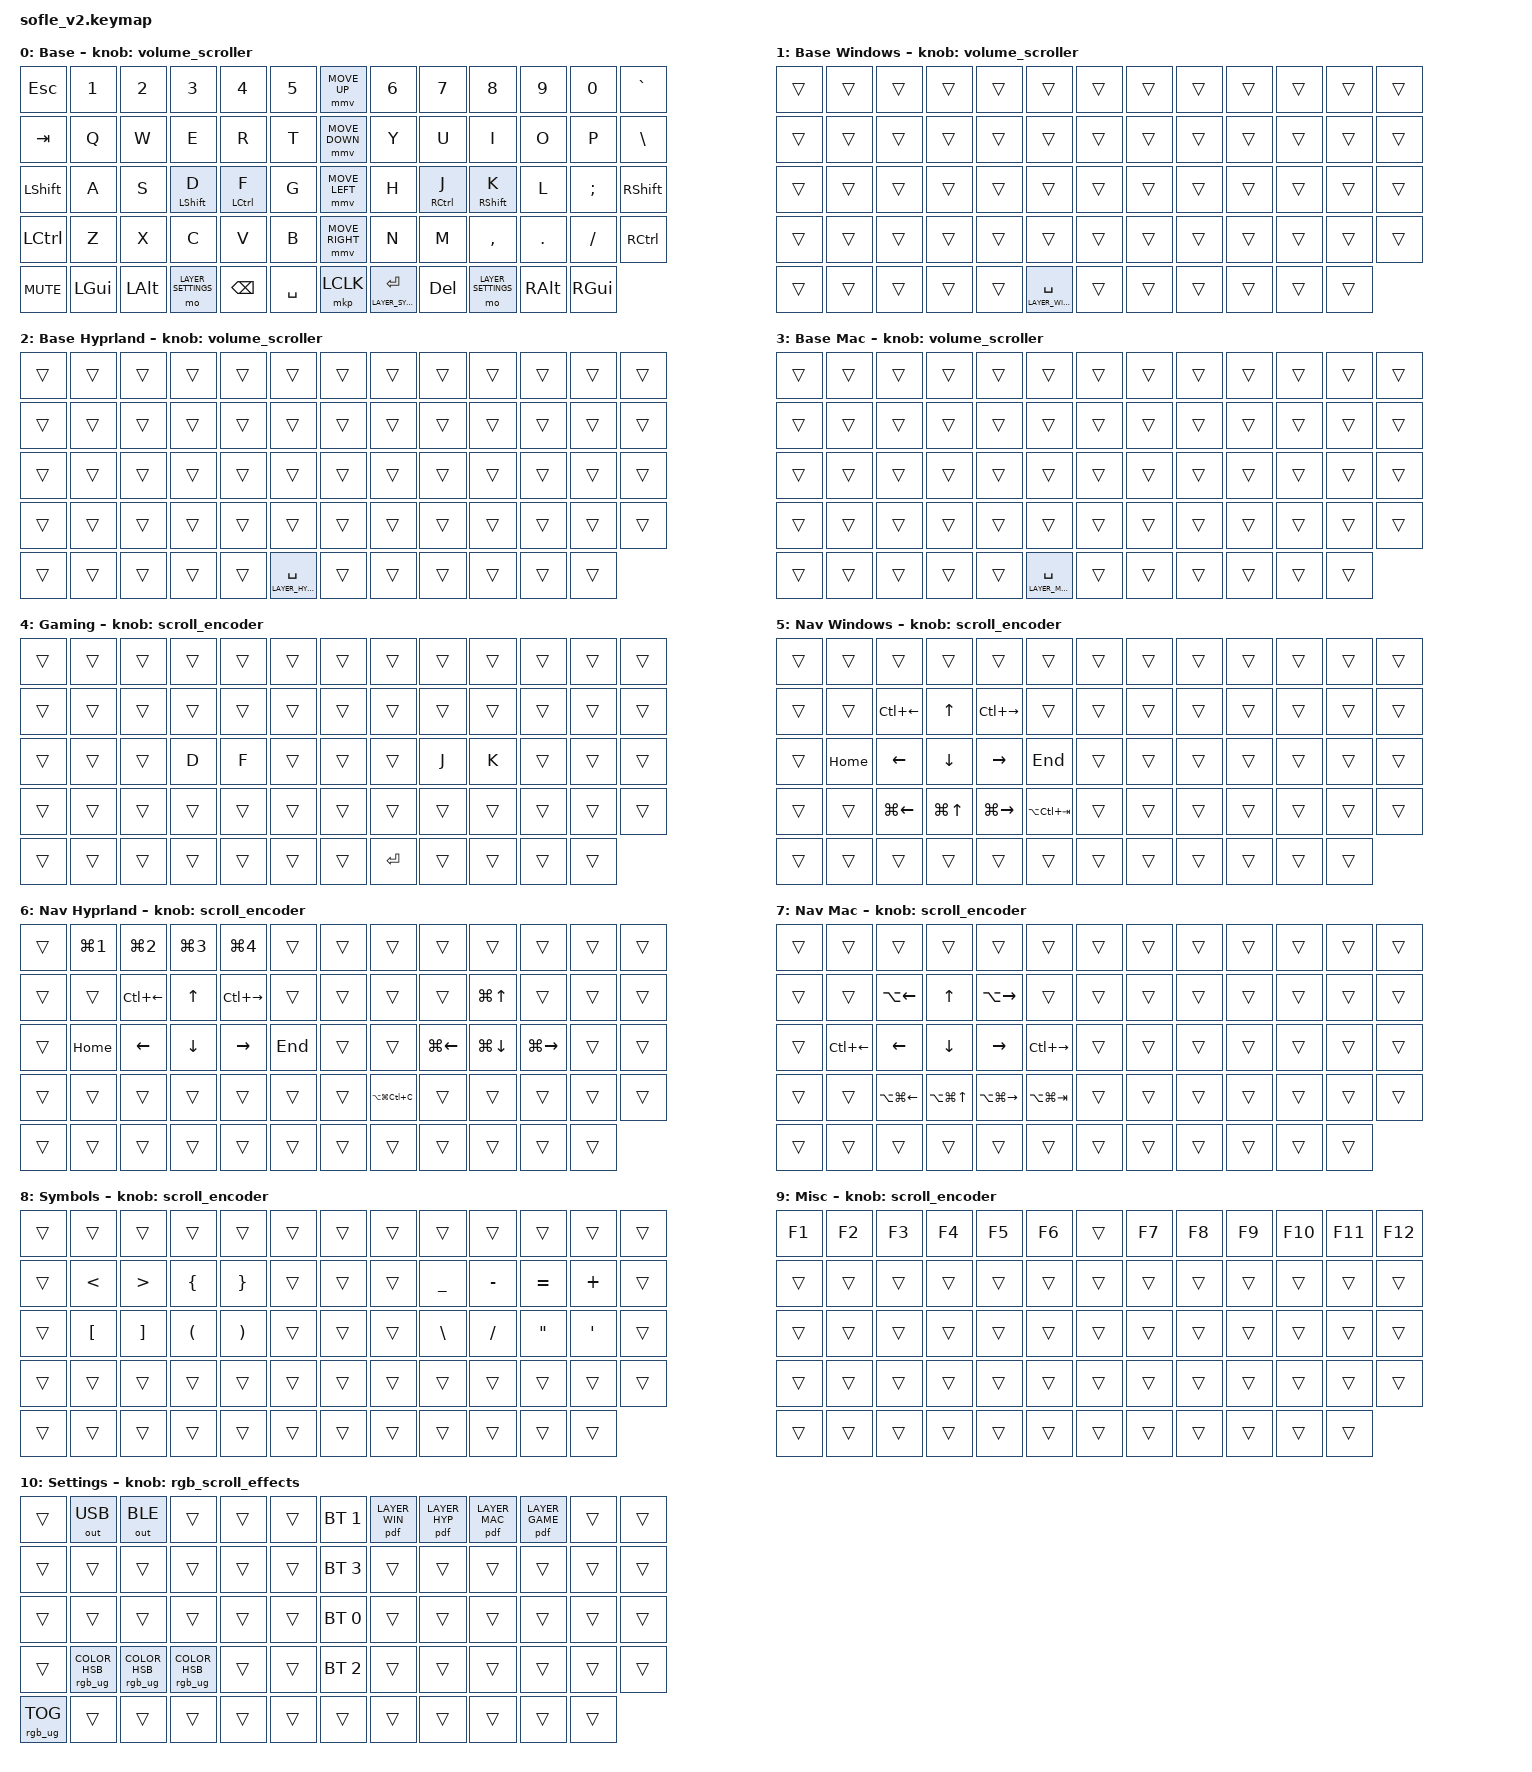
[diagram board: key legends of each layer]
#define ZMK_POINTING_DEFAULT_MOVE_VAL 1200  // 600
#define ZMK_POINTING_DEFAULT_SCRL_VAL 25   // 10

#include <input/processors.dtsi>
#include <zephyr/dt-bindings/input/input-event-codes.h>
#include <behaviors.dtsi>
#include <dt-bindings/zmk/bt.h>
#include <dt-bindings/zmk/keys.h>
#include <dt-bindings/zmk/outputs.h>
#include <dt-bindings/zmk/pointing.h>
#include <dt-bindings/zmk/rgb.h>

#define LAYER_WIN 1
#define LAYER_HYP 2
#define LAYER_MAC 3
#define LAYER_GAME 4
#define LAYER_WIN_NAV 5
#define LAYER_HYP_NAV 6
#define LAYER_MAC_NAV 7
#define LAYER_SYMBOLS 8
#define LAYER_MISC 9
#define LAYER_SETTINGS 10

&mmv_input_listener { input-processors = <&zip_xy_scaler 2 1>; };

&msc_input_listener { input-processors = <&zip_scroll_scaler 2 1>; };

&msc {
    acceleration-exponent = <1>;      // 0
    time-to-max-speed-ms = <100>;       // 300
    delay-ms = <0>;                   // 0
};

&mmv {
    time-to-max-speed-ms = <500>;
    acceleration-exponent = <1>;
    trigger-period-ms = <16>;
};

&soft_off { hold-time-ms = <2000>; };

&lt {
    flavor = "hold-preferred";
    require-prior-idle-ms = <75>;
    quick-tap-ms = <100>;
    tapping-term-ms = <220>;
};

/ {
    scroll_encoder: scroll_encoder {
        compatible = "zmk,behavior-sensor-rotate";
        #sensor-binding-cells = <0>;
        bindings = <&msc SCRL_DOWN>, <&msc SCRL_UP>;

        tap-ms = <100>;
    };

    behaviors {
        pdf: pdf {
            compatible = "zmk,behaviour-persistent-default-layer";
            #binding-cells = <1>;
        };

        hml: home_row_mod_left {
            compatible = "zmk,behavior-hold-tap";
            #binding-cells = <2>;
            flavor = "balanced";
            require-prior-idle-ms = <75>;
            tapping-term-ms = <175>;
            quick-tap-ms = <100>;
            bindings = <&kp>, <&kp>;

            //  hold-trigger-key-positions = <6 7 8 9 10 11 18 19 20 21 22 23 30 31 32 33 34 35 42 43 44 45 46 47 53 54 55 56 57>;
            //  hold-trigger-on-release;

            hold-trigger-key-positions = <7 20 33 46 47 34 21 8 9 22 35 48 49 36 23 10 11 24 37 50 51 38 25 12>;
            hold-trigger-on-release;
            label = "Home Row Mod Left";
        };

        hmr: home_row_mod_right {
            compatible = "zmk,behavior-hold-tap";
            #binding-cells = <2>;
            flavor = "balanced";
            require-prior-idle-ms = <75>;
            tapping-term-ms = <175>;
            quick-tap-ms = <100>;
            bindings = <&kp>, <&kp>;

            // hold-trigger-key-positions = < 0 1 2 3 4 5 12 13 14 15 16 17 24 25 26 27 28 29 36 37 38 39 40 41 48 49 50 51 52>; // List of keys on the left side of the keyboard
            // hold-trigger-on-release;

            hold-trigger-key-positions = <5 18 31 44 43 42 41 40 39 26 27 28 29 30 17 16 15 14 13 0 1 2 3 4 0 1 2 3 4 5 13 14 15 16 17 18 26 27 28 29 30 31 39 40 41 42 43 44>;
            hold-trigger-on-release;
            label = "Home Row Mod Right";
        };

        rgb_brightness: rgb_brightness {
            compatible = "zmk,behavior-sensor-rotate";
            label = "RGB_BRIGHTNESS";
            #sensor-binding-cells = <0>;
            bindings = <&rgb_ug RGB_BRD>, <&rgb_ug RGB_BRI>;
        };

        rgb_scroll_effects: rgb_scroll_effects {
            compatible = "zmk,behavior-sensor-rotate";
            label = "RGB_SCROLL_EFFECTS";
            #sensor-binding-cells = <0>;
            bindings = <&rgb_ug RGB_EFR>, <&rgb_ug RGB_EFF>;

            tap-ms = <25>;
        };

        rgb_hue: rgb_hue {
            compatible = "zmk,behavior-sensor-rotate";
            label = "RGB_HUE";
            #sensor-binding-cells = <0>;
            bindings = <&rgb_ug RGB_HUD>, <&rgb_ug RGB_HUI>;
        };

        volume_scroller: volume_scroller {
            compatible = "zmk,behavior-sensor-rotate";
            label = "VOLUME_SCROLLER";
            #sensor-binding-cells = <0>;
            bindings = <&kp K_VOLUME_UP>, <&kp K_VOLUME_DOWN>;
        };
    };

    combos {
        compatible = "zmk,combos";

        caps_word {
            bindings = <&caps_word>;
            key-positions = <26 38>;
        };

        clr_all_bt_profiles {
            bindings = <&bt BT_CLR_ALL>;
            key-positions = <0 12 26>;
            layers = <LAYER_SETTINGS>;
        };

        clr_bt_profile {
            bindings = <&bt BT_CLR>;
            key-positions = <0 12>;
            layers = <LAYER_SETTINGS>;
        };
    };

    keymap {
        compatible = "zmk,keymap";

        Base {
            label = "Base";
            display-name = "Base";
            bindings = <
&kp ESC         &kp N1        &kp N2        &kp N3              &kp N4         &kp N5       &mmv MOVE_UP     &kp N6                   &kp N7        &kp N8              &kp N9         &kp N0         &kp GRAVE
&kp TAB         &kp Q         &kp W         &kp E               &kp R          &kp T        &mmv MOVE_DOWN   &kp Y                    &kp U         &kp I               &kp O          &kp P          &kp BSLH
&kp LEFT_SHIFT  &kp A         &kp S         &hml LSHIFT D       &hml LCTRL F   &kp G        &mmv MOVE_LEFT   &kp H                    &hmr RCTRL J  &hmr RSHIFT K       &kp L          &kp SEMI       &kp RIGHT_SHIFT
&kp LCTRL       &kp Z         &kp X         &kp C               &kp V          &kp B        &mmv MOVE_RIGHT  &kp N                    &kp M         &kp COMMA           &kp DOT        &kp FSLH       &kp RCTRL
&kp C_MUTE      &kp LEFT_GUI  &kp LEFT_ALT  &mo LAYER_SETTINGS  &kp BACKSPACE  &kp SPACE    &mkp LCLK        &lt LAYER_SYMBOLS ENTER  &kp DEL       &mo LAYER_SETTINGS  &kp RIGHT_ALT  &kp RIGHT_GUI
            >;

            sensor-bindings = <&volume_scroller>;
        };

        Base_Windows {
            label = "Base Windows";
            display-name = "Base Windows";
            bindings = <
&trans  &trans  &trans  &trans  &trans  &trans                     &trans  &trans  &trans  &trans  &trans  &trans  &trans
&trans  &trans  &trans  &trans  &trans  &trans                     &trans  &trans  &trans  &trans  &trans  &trans  &trans
&trans  &trans  &trans  &trans  &trans  &trans                     &trans  &trans  &trans  &trans  &trans  &trans  &trans
&trans  &trans  &trans  &trans  &trans  &trans                     &trans  &trans  &trans  &trans  &trans  &trans  &trans
&trans  &trans  &trans  &trans  &trans  &lt LAYER_WIN_NAV SPACE    &trans  &trans  &trans  &trans  &trans  &trans
            >;

            sensor-bindings = <&volume_scroller>;
        };

        Base_Hyprland {
            label = "Base Hyprland";
            display-name = "Base Hyprland";
            bindings = <
&trans  &trans  &trans  &trans  &trans  &trans                     &trans  &trans  &trans  &trans  &trans  &trans  &trans
&trans  &trans  &trans  &trans  &trans  &trans                     &trans  &trans  &trans  &trans  &trans  &trans  &trans
&trans  &trans  &trans  &trans  &trans  &trans                     &trans  &trans  &trans  &trans  &trans  &trans  &trans
&trans  &trans  &trans  &trans  &trans  &trans                     &trans  &trans  &trans  &trans  &trans  &trans  &trans
&trans  &trans  &trans  &trans  &trans  &lt LAYER_HYP_NAV SPACE    &trans  &trans  &trans  &trans  &trans  &trans
            >;

            sensor-bindings = <&volume_scroller>;
        };

        Base_Mac {
            bindings = <
&trans  &trans  &trans  &trans  &trans  &trans                     &trans  &trans  &trans  &trans  &trans  &trans  &trans
&trans  &trans  &trans  &trans  &trans  &trans                     &trans  &trans  &trans  &trans  &trans  &trans  &trans
&trans  &trans  &trans  &trans  &trans  &trans                     &trans  &trans  &trans  &trans  &trans  &trans  &trans
&trans  &trans  &trans  &trans  &trans  &trans                     &trans  &trans  &trans  &trans  &trans  &trans  &trans
&trans  &trans  &trans  &trans  &trans  &lt LAYER_MAC_NAV SPACE    &trans  &trans  &trans  &trans  &trans  &trans
            >;

            label = "Base Mac";
            sensor-bindings = <&volume_scroller>;
        };

        Gaming {
            bindings = <
&trans  &trans  &trans  &trans  &trans  &trans    &trans  &trans     &trans  &trans  &trans  &trans  &trans
&trans  &trans  &trans  &trans  &trans  &trans    &trans  &trans     &trans  &trans  &trans  &trans  &trans
&trans  &trans  &trans  &kp D   &kp F   &trans    &trans  &trans     &kp J   &kp K   &trans  &trans  &trans
&trans  &trans  &trans  &trans  &trans  &trans    &trans  &trans     &trans  &trans  &trans  &trans  &trans
&trans  &trans  &trans  &trans  &trans  &trans    &trans  &kp ENTER  &trans  &trans  &trans  &trans
            >;

            display-name = "Gaming";
            sensor-bindings = <&scroll_encoder>;
            label = "Gaming";
        };

        Nav_Win {
            label = "Navigation Windows";
            display-name = "Nav Windows";
            bindings = <
&trans  &trans    &trans        &trans            &trans         &trans             &trans  &trans  &trans  &trans  &trans  &trans  &trans
&trans  &trans    &kp LC(LEFT)  &kp UP_ARROW      &kp LC(RIGHT)  &trans             &trans  &trans  &trans  &trans  &trans  &trans  &trans
&trans  &kp HOME  &kp LEFT      &kp DOWN          &kp RIGHT      &kp END            &trans  &trans  &trans  &trans  &trans  &trans  &trans
&trans  &trans    &kp LG(LEFT)  &kp LG(UP_ARROW)  &kp LG(RIGHT)  &kp LA(LC(TAB))    &trans  &trans  &trans  &trans  &trans  &trans  &trans
&trans  &trans    &trans        &trans            &trans         &trans             &trans  &trans  &trans  &trans  &trans  &trans
            >;

            sensor-bindings = <&scroll_encoder>;
        };

        Nav_Hyprland {
            label = "Navigation Hyprland";
            display-name = "Nav Hyprland";
            bindings = <
&trans  &kp LG(N1)  &kp LG(N2)    &kp LG(N3)    &kp LG(N4)     &trans     &trans  &trans             &trans        &trans        &trans         &trans  &trans
&trans  &trans      &kp LC(LEFT)  &kp UP_ARROW  &kp LC(RIGHT)  &trans     &trans  &trans             &trans        &kp LG(UP)    &trans         &trans  &trans
&trans  &kp HOME    &kp LEFT      &kp DOWN      &kp RIGHT      &kp END    &trans  &trans             &kp LG(LEFT)  &kp LG(DOWN)  &kp LG(RIGHT)  &trans  &trans
&trans  &trans      &trans        &trans        &trans         &trans     &trans  &kp LA(LG(LC(C)))  &trans        &trans        &trans         &trans  &trans
&trans  &trans      &trans        &trans        &trans         &trans     &trans  &trans             &trans        &trans        &trans         &trans
            >;

            sensor-bindings = <&scroll_encoder>;
        };

        Nav_Mac {
            label = "Navigation Mac";
            display-name = "Nav Mac";
            bindings = <
&trans  &trans        &trans            &trans          &trans             &trans             &trans  &trans  &trans  &trans  &trans  &trans  &trans
&trans  &trans        &kp LA(LEFT)      &kp UP          &kp LA(RIGHT)      &trans             &trans  &trans  &trans  &trans  &trans  &trans  &trans
&trans  &kp LC(LEFT)  &kp LEFT          &kp DOWN        &kp RIGHT          &kp LC(RIGHT)      &trans  &trans  &trans  &trans  &trans  &trans  &trans
&trans  &trans        &kp LA(LG(LEFT))  &kp LA(LG(UP))  &kp LA(LG(RIGHT))  &kp LA(LG(TAB))    &trans  &trans  &trans  &trans  &trans  &trans  &trans
&trans  &trans        &trans            &trans          &trans             &trans             &trans  &trans  &trans  &trans  &trans  &trans
            >;

            sensor-bindings = <&scroll_encoder>;
        };

        Symbols {
            label = "Symbols";
            display-name = "Symbols";
            bindings = <
&trans  &trans         &trans            &trans                &trans                 &trans    &trans  &trans  &trans          &trans     &trans             &trans    &trans
&trans  &kp LESS_THAN  &kp GREATER_THAN  &kp LEFT_BRACE        &kp RIGHT_BRACE        &trans    &trans  &trans  &kp UNDERSCORE  &kp MINUS  &kp EQUAL          &kp PLUS  &trans
&trans  &kp LBKT       &kp RBKT          &kp LEFT_PARENTHESIS  &kp RIGHT_PARENTHESIS  &trans    &trans  &trans  &kp BSLH        &kp FSLH   &kp DOUBLE_QUOTES  &kp APOS  &trans
&trans  &trans         &trans            &trans                &trans                 &trans    &trans  &trans  &trans          &trans     &trans             &trans    &trans
&trans  &trans         &trans            &trans                &trans                 &trans    &trans  &trans  &trans          &trans     &trans             &trans
            >;

            sensor-bindings = <&scroll_encoder>;
        };

        Misc {
            label = "Miscellaneous";
            display-name = "Misc";
            bindings = <
&kp F1  &kp F2  &kp F3  &kp F4  &kp F5  &kp F6    &trans  &kp F7  &kp F8  &kp F9  &kp F10  &kp F11  &kp F12
&trans  &trans  &trans  &trans  &trans  &trans    &trans  &trans  &trans  &trans  &trans   &trans   &trans
&trans  &trans  &trans  &trans  &trans  &trans    &trans  &trans  &trans  &trans  &trans   &trans   &trans
&trans  &trans  &trans  &trans  &trans  &trans    &trans  &trans  &trans  &trans  &trans   &trans   &trans
&trans  &trans  &trans  &trans  &trans  &trans    &trans  &trans  &trans  &trans  &trans   &trans
            >;

            sensor-bindings = <&scroll_encoder>;
        };

        Settings {
            label = "Settings";
            display-name = "Settings";
            bindings = <
&trans           &out OUT_USB                    &out OUT_BLE                      &trans                             &trans  &trans    &bt BT_SEL 1  &pdf LAYER_WIN  &pdf LAYER_HYP  &pdf LAYER_MAC  &pdf LAYER_GAME  &trans  &trans
&trans           &trans                          &trans                            &trans                             &trans  &trans    &bt BT_SEL 3  &trans          &trans          &trans          &trans           &trans  &trans
&trans           &trans                          &trans                            &trans                             &trans  &trans    &bt BT_SEL 0  &trans          &trans          &trans          &trans           &trans  &trans
&trans           &rgb_ug RGB_COLOR_HSB(0,0,100)  &rgb_ug RGB_COLOR_HSB(264,82,46)  &rgb_ug RGB_COLOR_HSB(235,100,50)  &trans  &trans    &bt BT_SEL 2  &trans          &trans          &trans          &trans           &trans  &trans
&rgb_ug RGB_TOG  &trans                          &trans                            &trans                             &trans  &trans    &trans        &trans          &trans          &trans          &trans           &trans
            >;

            sensor-bindings = <&rgb_scroll_effects>;
        };
    };

    conditional_layers {
        compatible = "zmk,conditional-layers";

        Misc_Win {
            if-layers = <LAYER_WIN_NAV LAYER_SYMBOLS>;
            then-layer = <LAYER_MISC>;
        };

        Misc_Hyprland {
            if-layers = <LAYER_HYP_NAV LAYER_SYMBOLS>;
            then-layer = <LAYER_MISC>;
        };

        Misc_Mac {
            if-layers = <LAYER_MAC_NAV LAYER_SYMBOLS>;
            then-layer = <LAYER_MISC>;
        };
    };
};
